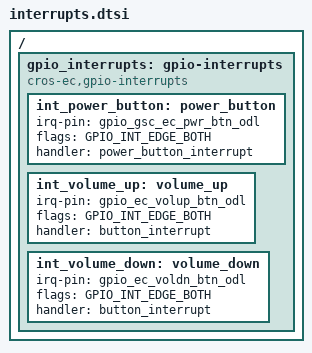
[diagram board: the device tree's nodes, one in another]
/* Copyright 2023 The ChromiumOS Authors
 * Use of this source code is governed by a BSD-style license that can be
 * found in the LICENSE file.
 */

/ {
	gpio_interrupts: gpio-interrupts {
		compatible = "cros-ec,gpio-interrupts";

		int_power_button: power_button {
			irq-pin = <&gpio_gsc_ec_pwr_btn_odl>;
			flags = <GPIO_INT_EDGE_BOTH>;
			handler = "power_button_interrupt";
		};
		int_volume_up: volume_up {
			irq-pin = <&gpio_ec_volup_btn_odl>;
			flags = <GPIO_INT_EDGE_BOTH>;
			handler = "button_interrupt";
		};
		int_volume_down: volume_down {
			irq-pin = <&gpio_ec_voldn_btn_odl>;
			flags = <GPIO_INT_EDGE_BOTH>;
			handler = "button_interrupt";
		};
	};
};

#include "interrupts_motionsense.dtsi"
